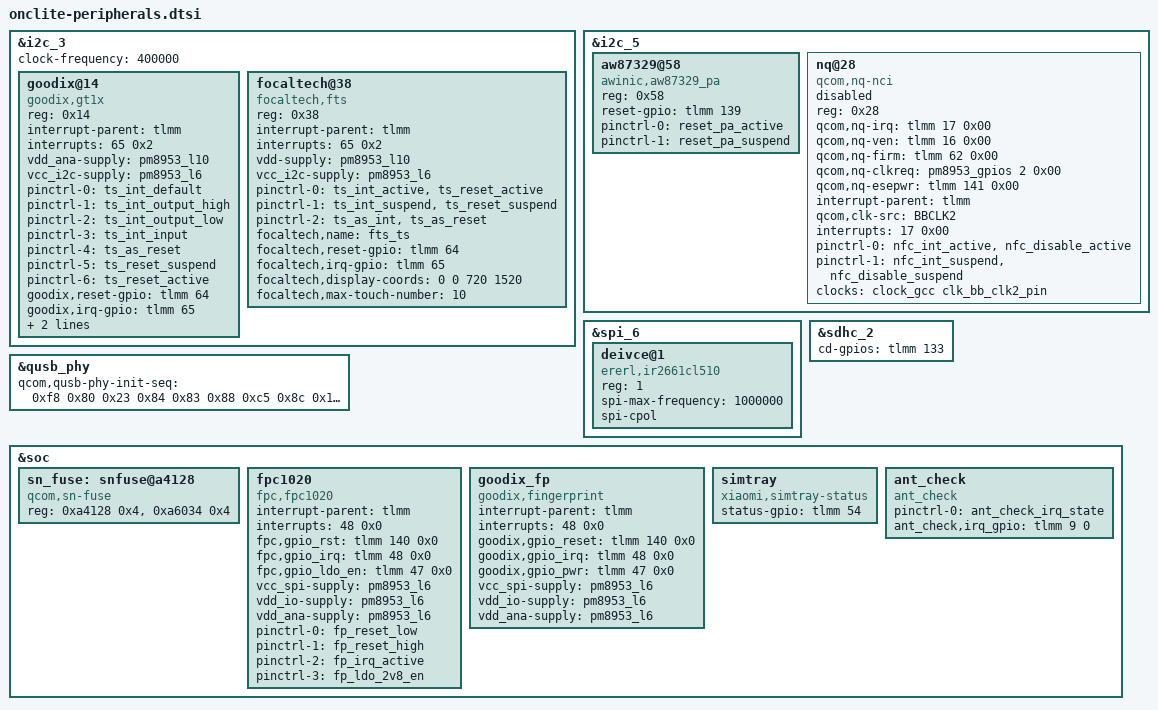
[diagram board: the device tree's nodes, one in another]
/* SPDX-License-Identifier: GPL-2.0-only */

/* i2c3 — BLSP1 QUP3 — touch ICs */
&i2c_3 {
	status = "ok";
	clock-frequency = <400000>;

	/* Goodix GT1X touchscreen */
	goodix@14 {
		compatible = "goodix,gt1x";
		reg = <0x14>;
		interrupt-parent = <&tlmm>;
		interrupts = <65 0x2>;
		vdd_ana-supply = <&pm8953_l10>;
		vcc_i2c-supply = <&pm8953_l6>;
		pinctrl-names = "default", "int-output-high", "int-output-low",
				"int-input", "erst_as_default", "erst_output_low",
				"erst_output_high";
		pinctrl-0 = <&ts_int_default>;
		pinctrl-1 = <&ts_int_output_high>;
		pinctrl-2 = <&ts_int_output_low>;
		pinctrl-3 = <&ts_int_input>;
		pinctrl-4 = <&ts_as_reset>;
		pinctrl-5 = <&ts_reset_suspend>;
		pinctrl-6 = <&ts_reset_active>;
		goodix,reset-gpio = <&tlmm 64 0x00>;
		goodix,irq-gpio = <&tlmm 65 0x00>;
		goodix,default-config0 = [
			FF D0 02 F0 05 0A 3C 00 00 88 4E 0F 5A 46 3E
			11 00 0C 08 1E 01 33 00 00 00 00 00 18 00 00
			A0 0C 32 32 28 5A 11 22 91 A0 B4 00 00 00 00
			00 00 00 00 00 50 BE 00 00 8E 20 1D 32 34 5A
			0D 00 2E 53 24 7B 00 00 32 AB 26 95 2E 80 36
			7F 3F 00 00 00 00 00 00 00 00 00 00 00 00 00
			00 00 00 00 00 00 00 00 00 00 00 00 00 00 1E
			50 40 94 D4 28 12 03 EE 26 AA 2E 82 36 72 3F
			6E 47 6E 00 00 00 00 00 00 00 00 00 00 00 00
			00 00 00 00 00 00 00 00 00 00 00 1F 1D 1B 1A
			19 18 17 16 15 14 13 12 10 0F 01 02 03 04 05
			06 07 08 09 0A 0B 0C 0D 0E FF FF FF 06 08 0C
			12 13 14 15 17 18 19 1A 1B 1C 1D FF FF FF FF
			FF FF FF FF FF FF FF FF FF FF FF FF FF FF 00
			F8 0A 23 23 50 5D 54 50 3C 05 32 00 00 04 40
			00 8A 02 40 00 AA 00 22 22 00 40 D1 4C 01 33
			00 00 00 00 00 00 00 10 00 28 A5 00 00 00 00
			32 08 65 00 00 00 12 6E 19 01 64 03 64 28 50
			65 0D 00 00 00 00 00 00 00 00 00 00 00 00 1E
			0A 01 DC 00 00 00 14 28 46 11 20 A2 34 66 E4
			0C 5A 00 0F 23 02 3C 0E 02 01 01 01 00 00 00
			00 16 00 00 00 00 00 00 00 00 00 00 00 00 00
			00 00 00 00 00 00 00 00 00 00 00 00 00 00 00
			00 00 00 00 00 00 00 00 00 00 00 00 00 00 00
			00 00 00 00 00 B7 70
			];
	};

	/* FocalTech FTS touchscreen */
	focaltech@38 {
		compatible = "focaltech,fts";
		reg = <0x38>;
		interrupt-parent = <&tlmm>;
		interrupts = <65 0x2>;
		vdd-supply = <&pm8953_l10>;
		vcc_i2c-supply = <&pm8953_l6>;
		pinctrl-names = "pmx_ts_irqrst_active", "pmx_ts_irqrst_suspend",
				"pmx_ts_irqrst_release";
		pinctrl-0 = <&ts_int_active &ts_reset_active>;
		pinctrl-1 = <&ts_int_suspend &ts_reset_suspend>;
		pinctrl-2 = <&ts_as_int &ts_as_reset>;
		focaltech,name = "fts_ts";
		focaltech,reset-gpio = <&tlmm 64 0x00>;
		focaltech,irq-gpio = <&tlmm 65 0x02>;
		focaltech,display-coords = <0 0 720 1520>;
		focaltech,max-touch-number = <10>;
	};
};

/* i2c5 — BLSP2 QUP1 — speaker amp + NFC */
&i2c_5 {
	status = "ok";

	/* Awinic AW87329 speaker PA */
	aw87329@58 {
		status = "okay";
		compatible = "awinic,aw87329_pa";
		reg = <0x58>;
		reset-gpio = <&tlmm 139 0>;
		pinctrl-names = "reset_pa_act", "reset_pa_sus";
		pinctrl-0 = <&reset_pa_active>;
		pinctrl-1 = <&reset_pa_suspend>;
	};

	/* NFC — not populated on onclite */
	nq@28 {
		status = "disabled";
		compatible = "qcom,nq-nci";
		reg = <0x28>;
		qcom,nq-irq = <&tlmm 17 0x00>;
		qcom,nq-ven = <&tlmm 16 0x00>;
		qcom,nq-firm = <&tlmm 62 0x00>;
		qcom,nq-clkreq = <&pm8953_gpios 2 0x00>;
		qcom,nq-esepwr = <&tlmm 141 0x00>;
		interrupt-parent = <&tlmm>;
		qcom,clk-src = "BBCLK2";
		interrupts = <17 0x00>;
		interrupt-names = "nfc_irq";
		pinctrl-names = "nfc_active", "nfc_suspend";
		pinctrl-0 = <&nfc_int_active &nfc_disable_active>;
		pinctrl-1 = <&nfc_int_suspend &nfc_disable_suspend>;
		clocks = <&clock_gcc clk_bb_clk2_pin>;
		clock-names = "ref_clk";
	};
};

/* spi6 — BLSP2 QUP2 — IR blaster */
&spi_6 {
	status = "ok";

	/* Ererl IR2661CL510 IR transmitter */
	deivce@1 {
		compatible = "ererl,ir2661cl510";
		#address-cells = <1>;
		#size-cells = <1>;
		reg = <1>;
		spi-max-frequency = <1000000>;
		spi-cpol;
	};
};

/* SD card — card detect GPIO polarity */
&sdhc_2 {
	cd-gpios = <&tlmm 133 0x0>;
};

/* QUSB PHY tuning for onclite */
&qusb_phy {
	qcom,qusb-phy-init-seq = <0xf8 0x80
				0x23 0x84
				0x83 0x88
				0xc5 0x8c
				0x14 0x9c
				0x30 0x08
				0x79 0x0c
				0x21 0x10
				0x00 0x90
				0x9f 0x1c
				0x00 0x18>;
};

/* SN fuse state readout */
&soc {
	sn_fuse: snfuse@a4128 {
		compatible = "qcom,sn-fuse";
		reg = <0xa4128 0x4>,
		      <0xa6034 0x4>;
		reg-names = "sn-base", "fuse-state";
	};

	/* FPC1020 fingerprint sensor */
	fpc1020 {
		status = "ok";
		compatible = "fpc,fpc1020";
		interrupt-parent = <&tlmm>;
		interrupts = <48 0x0>;
		fpc,gpio_rst = <&tlmm 140 0x0>;
		fpc,gpio_irq = <&tlmm 48 0x0>;
		fpc,gpio_ldo_en = <&tlmm 47 0x0>;
		vcc_spi-supply = <&pm8953_l6>;
		vdd_io-supply = <&pm8953_l6>;
		vdd_ana-supply = <&pm8953_l6>;
		pinctrl-names = "fpc1020_reset_reset",
				"fpc1020_reset_active",
				"fpc1020_irq_active",
				"fpc1020_ldo_2v8_en";
		pinctrl-0 = <&fp_reset_low>;
		pinctrl-1 = <&fp_reset_high>;
		pinctrl-2 = <&fp_irq_active>;
		pinctrl-3 = <&fp_ldo_2v8_en>;
	};

	/* Goodix fingerprint sensor */
	goodix_fp {
		status = "ok";
		compatible = "goodix,fingerprint";
		interrupt-parent = <&tlmm>;
		interrupts = <48 0x0>;
		goodix,gpio_reset = <&tlmm 140 0x0>;
		goodix,gpio_irq = <&tlmm 48 0x0>;
		goodix,gpio_pwr = <&tlmm 47 0x0>;
		vcc_spi-supply = <&pm8953_l6>;
		vdd_io-supply = <&pm8953_l6>;
		vdd_ana-supply = <&pm8953_l6>;
	};

	/* SIM tray presence detect */
	simtray {
		compatible = "xiaomi,simtray-status";
		status-gpio = <&tlmm 54 0x00>;
	};

	/* Antenna presence detect */
	ant_check {
		compatible = "ant_check";
		pinctrl-names = "ant_check_irq_state";
		pinctrl-0 = <&ant_check_irq_state>;
		ant_check,irq_gpio = <&tlmm 9 0>;
	};
};
